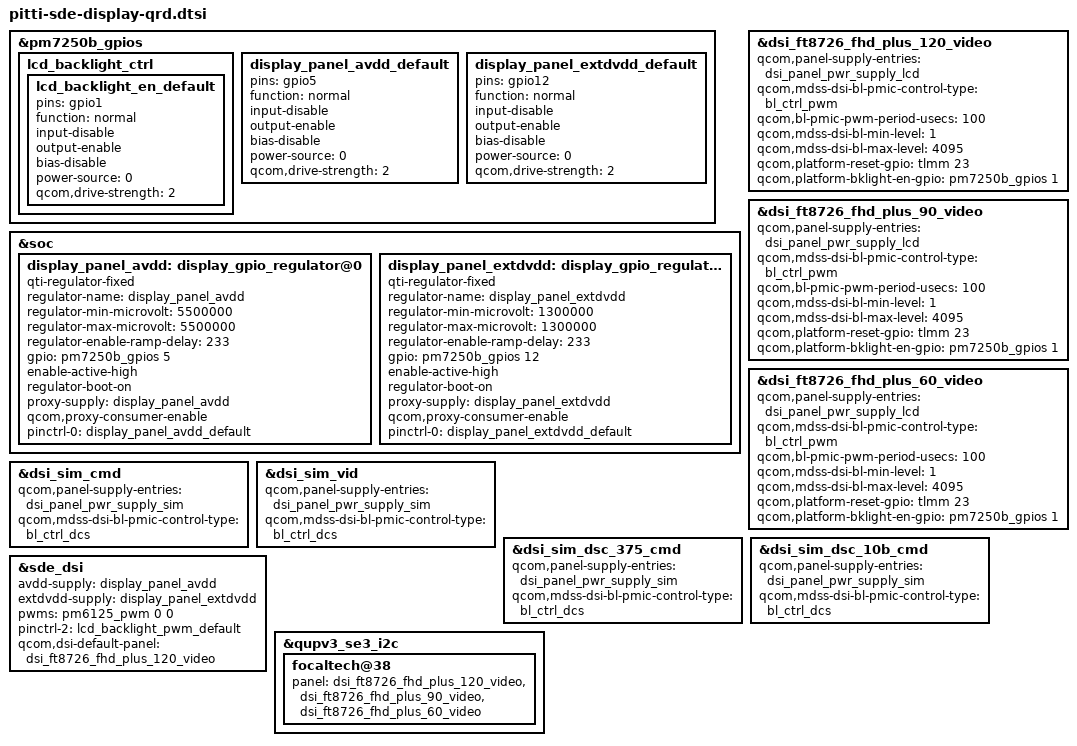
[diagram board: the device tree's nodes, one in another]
#include "pitti-sde-display.dtsi"

&pm7250b_gpios {
	lcd_backlight_ctrl {
		lcd_backlight_en_default: lcd_backlight_en_default {
			pins = "gpio1";
			function = "normal";
			input-disable;
			output-enable;
			bias-disable;
			power-source = <0>;
			qcom,drive-strength = <2>;
		};
	};

	display_panel_avdd_default: display_panel_avdd_default {
		pins = "gpio5";
		function = "normal";
		input-disable;
		output-enable;
		bias-disable;
		power-source = <0>;
		qcom,drive-strength = <2>;
	};

	display_panel_extdvdd_default: display_panel_extdvdd_default {
		pins = "gpio12";
		function = "normal";
		input-disable;
		output-enable;
		bias-disable;
		power-source = <0>;
		qcom,drive-strength = <2>;
	};
};

&soc {
	display_panel_avdd: display_gpio_regulator@0 {
		compatible = "qti-regulator-fixed";
		regulator-name = "display_panel_avdd";
		regulator-min-microvolt = <5500000>;
		regulator-max-microvolt = <5500000>;
		regulator-enable-ramp-delay = <233>;
		gpio = <&pm7250b_gpios 5 0>;
		enable-active-high;
		regulator-boot-on;
		proxy-supply = <&display_panel_avdd>;
		qcom,proxy-consumer-enable;
		pinctrl-names = "default";
		pinctrl-0 = <&display_panel_avdd_default>;
	};

	display_panel_extdvdd: display_gpio_regulator@1 {
		compatible = "qti-regulator-fixed";
		regulator-name = "display_panel_extdvdd";
		regulator-min-microvolt = <1300000>;
		regulator-max-microvolt = <1300000>;
		regulator-enable-ramp-delay = <233>;
		gpio = <&pm7250b_gpios 12 0>;
		enable-active-high;
		regulator-boot-on;
		proxy-supply = <&display_panel_extdvdd>;
		qcom,proxy-consumer-enable;
		pinctrl-names = "default";
		pinctrl-0 = <&display_panel_extdvdd_default>;
	};
};

&dsi_ft8726_fhd_plus_120_video {
	qcom,panel-supply-entries = <&dsi_panel_pwr_supply_lcd>;
	qcom,mdss-dsi-bl-pmic-control-type = "bl_ctrl_pwm";
	qcom,bl-pmic-pwm-period-usecs = <100>;
	qcom,mdss-dsi-bl-min-level = <1>;
	qcom,mdss-dsi-bl-max-level = <4095>;
	qcom,platform-reset-gpio = <&tlmm 23 0>;
	qcom,platform-bklight-en-gpio = <&pm7250b_gpios 1 0>;
};

&dsi_ft8726_fhd_plus_90_video {
	qcom,panel-supply-entries = <&dsi_panel_pwr_supply_lcd>;
	qcom,mdss-dsi-bl-pmic-control-type = "bl_ctrl_pwm";
	qcom,bl-pmic-pwm-period-usecs = <100>;
	qcom,mdss-dsi-bl-min-level = <1>;
	qcom,mdss-dsi-bl-max-level = <4095>;
	qcom,platform-reset-gpio = <&tlmm 23 0>;
	qcom,platform-bklight-en-gpio = <&pm7250b_gpios 1 0>;
};

&dsi_ft8726_fhd_plus_60_video {
	qcom,panel-supply-entries = <&dsi_panel_pwr_supply_lcd>;
	qcom,mdss-dsi-bl-pmic-control-type = "bl_ctrl_pwm";
	qcom,bl-pmic-pwm-period-usecs = <100>;
	qcom,mdss-dsi-bl-min-level = <1>;
	qcom,mdss-dsi-bl-max-level = <4095>;
	qcom,platform-reset-gpio = <&tlmm 23 0>;
	qcom,platform-bklight-en-gpio = <&pm7250b_gpios 1 0>;
};

&dsi_sim_cmd {
	qcom,panel-supply-entries = <&dsi_panel_pwr_supply_sim>;
	qcom,mdss-dsi-bl-pmic-control-type = "bl_ctrl_dcs";
};

&dsi_sim_vid {
	qcom,panel-supply-entries = <&dsi_panel_pwr_supply_sim>;
	qcom,mdss-dsi-bl-pmic-control-type = "bl_ctrl_dcs";
};

&dsi_sim_dsc_375_cmd {
	qcom,panel-supply-entries = <&dsi_panel_pwr_supply_sim>;
	qcom,mdss-dsi-bl-pmic-control-type = "bl_ctrl_dcs";
};

&dsi_sim_dsc_10b_cmd {
	qcom,panel-supply-entries = <&dsi_panel_pwr_supply_sim>;
	qcom,mdss-dsi-bl-pmic-control-type = "bl_ctrl_dcs";
};

&sde_dsi {
	avdd-supply = <&display_panel_avdd>;
	extdvdd-supply = <&display_panel_extdvdd>;

	pwms = <&pm6125_pwm 0 0>;

	pinctrl-names = "panel_active", "panel_suspend", "pwm_pin";
	pinctrl-2 = <&lcd_backlight_pwm_default>;

	qcom,dsi-default-panel = <&dsi_ft8726_fhd_plus_120_video>;
};

&qupv3_se3_i2c {
	focaltech@38 {
		panel = <&dsi_ft8726_fhd_plus_120_video
			&dsi_ft8726_fhd_plus_90_video
			&dsi_ft8726_fhd_plus_60_video>;
	};
};
